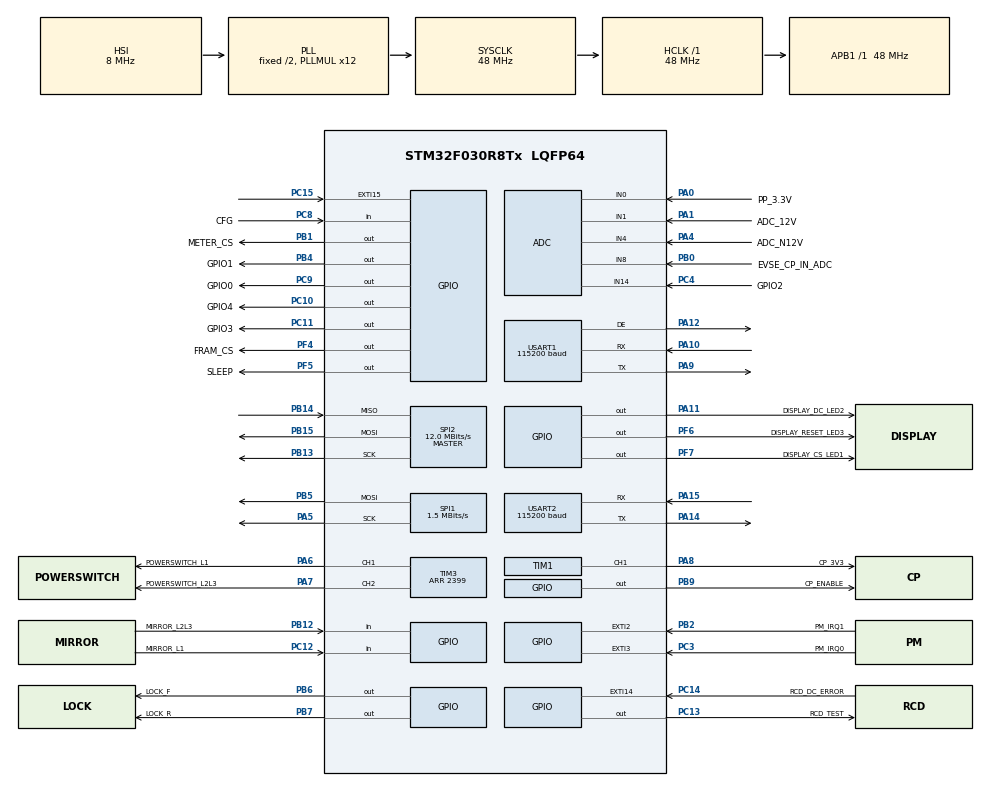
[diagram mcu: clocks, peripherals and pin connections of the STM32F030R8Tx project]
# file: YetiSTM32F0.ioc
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ADC.EOCSelection=ADC_EOC_SEQ_CONV
ADC.Overrun=ADC_OVR_DATA_OVERWRITTEN
ADC.SamplingTime=ADC_SAMPLETIME_13CYCLES_5
CRC.InputDataInversionMode=CRC_INPUTDATA_INVERSION_BYTE
CRC.OutputDataInversionMode=CRC_OUTPUTDATA_INVERSION_ENABLE
Dma.ADC.0.Direction=DMA_PERIPH_TO_MEMORY
Dma.ADC.0.Instance=DMA1_Channel1
Dma.ADC.0.MemDataAlignment=DMA_MDATAALIGN_HALFWORD
Dma.ADC.0.MemInc=DMA_MINC_ENABLE
Dma.ADC.0.Mode=DMA_NORMAL
Dma.ADC.0.PeriphDataAlignment=DMA_PDATAALIGN_HALFWORD
Dma.ADC.0.PeriphInc=DMA_PINC_DISABLE
Dma.ADC.0.Priority=DMA_PRIORITY_HIGH
Dma.Request0=ADC
Dma.Request1=USART2_TX
Dma.Request2=USART2_RX
Dma.Request3=SPI1_TX
Dma.SPI1_TX.3.Direction=DMA_MEMORY_TO_PERIPH
Dma.SPI1_TX.3.Instance=DMA1_Channel3
Dma.SPI1_TX.3.MemDataAlignment=DMA_MDATAALIGN_BYTE
Dma.SPI1_TX.3.MemInc=DMA_MINC_ENABLE
Dma.SPI1_TX.3.Mode=DMA_NORMAL
Dma.SPI1_TX.3.PeriphDataAlignment=DMA_PDATAALIGN_BYTE
Dma.SPI1_TX.3.PeriphInc=DMA_PINC_DISABLE
Dma.SPI1_TX.3.Priority=DMA_PRIORITY_LOW
Dma.USART2_RX.2.Direction=DMA_PERIPH_TO_MEMORY
Dma.USART2_RX.2.Instance=DMA1_Channel5
Dma.USART2_RX.2.MemDataAlignment=DMA_MDATAALIGN_BYTE
Dma.USART2_RX.2.MemInc=DMA_MINC_ENABLE
Dma.USART2_RX.2.Mode=DMA_CIRCULAR
Dma.USART2_RX.2.PeriphDataAlignment=DMA_PDATAALIGN_BYTE
Dma.USART2_RX.2.PeriphInc=DMA_PINC_DISABLE
Dma.USART2_RX.2.Priority=DMA_PRIORITY_LOW
Dma.USART2_TX.1.Direction=DMA_MEMORY_TO_PERIPH
Dma.USART2_TX.1.Instance=DMA1_Channel4
Dma.USART2_TX.1.MemDataAlignment=DMA_MDATAALIGN_BYTE
Dma.USART2_TX.1.MemInc=DMA_MINC_ENABLE
Dma.USART2_TX.1.Mode=DMA_NORMAL
Dma.USART2_TX.1.PeriphDataAlignment=DMA_PDATAALIGN_BYTE
Dma.USART2_TX.1.PeriphInc=DMA_PINC_DISABLE
Dma.USART2_TX.1.Priority=DMA_PRIORITY_LOW
Mcu.Family=STM32F0
Mcu.Name=STM32F030R8Tx
Mcu.Package=LQFP64
NVIC.DMA1_Channel1_IRQn=true\:0\:0\:false\:false\:true\:false\:true\:true
NVIC.DMA1_Channel2_3_IRQn=true\:0\:0\:false\:false\:true\:false\:true\:true
NVIC.DMA1_Channel4_5_IRQn=true\:0\:0\:false\:false\:true\:false\:true\:true
NVIC.EXTI2_3_IRQn=true\:0\:0\:false\:false\:true\:true\:true\:true
NVIC.EXTI4_15_IRQn=true\:0\:0\:false\:false\:true\:true\:true\:true
NVIC.TIM1_BRK_UP_TRG_COM_IRQn=true\:0\:0\:false\:false\:true\:true\:true\:true
NVIC.TIM1_CC_IRQn=true\:0\:0\:false\:false\:true\:true\:true\:true
NVIC.USART2_IRQn=true\:0\:0\:false\:false\:true\:true\:true\:true
PA0.GPIO_Label=PP_3.3V
PA0.Mode=IN0
PA0.Signal=ADC_IN0
PA1.GPIO_Label=ADC_12V
PA1.Mode=IN1
PA1.Signal=ADC_IN1
PA10.GPIO_Speed=GPIO_SPEED_FREQ_LOW
PA10.Mode=Asynchronous
PA10.Signal=USART1_RX
PA11.GPIO_Label=DISPLAY_DC_LED2
PA11.Signal=GPIO_Output
PA12.GPIO_Speed=GPIO_SPEED_FREQ_LOW
PA12.Mode=Hardware Flow Control (RS485)
PA12.Signal=USART1_DE
PA14.GPIO_PuPd=GPIO_PULLUP
PA14.GPIO_Speed=GPIO_SPEED_FREQ_LOW
PA14.Mode=Asynchronous
PA14.Signal=USART2_TX
PA15.GPIO_PuPd=GPIO_PULLUP
PA15.GPIO_Speed=GPIO_SPEED_FREQ_LOW
PA15.Mode=Asynchronous
PA15.Signal=USART2_RX
PA4.GPIO_Label=ADC_N12V
PA4.Mode=IN4
PA4.Signal=ADC_IN4
PA5.Mode=TX_Only_Simplex_Unidirect_Master
PA5.Signal=SPI1_SCK
PA6.GPIO_Label=POWERSWITCH_L1
PA6.GPIO_PuPd=GPIO_PULLDOWN
PA6.Signal=S_TIM3_CH1
PA7.GPIO_Label=POWERSWITCH_L2L3
PA7.GPIO_PuPd=GPIO_PULLDOWN
PA7.Signal=S_TIM3_CH2
PA8.GPIO_Label=CP_3V3
PA8.Signal=S_TIM1_CH1
PA9.GPIO_Speed=GPIO_SPEED_FREQ_LOW
PA9.Mode=Asynchronous
PA9.Signal=USART1_TX
PB0.GPIO_Label=EVSE_CP_IN_ADC
PB0.Mode=IN8
PB0.Signal=ADC_IN8
PB1.GPIO_Label=METER_CS
PB1.GPIO_PuPd=GPIO_PULLUP
PB1.Signal=GPIO_Output
PB12.GPIO_Label=MIRROR_L2L3
PB12.GPIO_PuPd=GPIO_PULLDOWN
PB12.Signal=GPIO_Input
PB13.Mode=Full_Duplex_Master
PB13.Signal=SPI2_SCK
PB14.Mode=Full_Duplex_Master
PB14.Signal=SPI2_MISO
PB15.Mode=Full_Duplex_Master
PB15.Signal=SPI2_MOSI
PB2.GPIO_Label=PM_IRQ1
PB2.GPIO_PuPd=GPIO_PULLUP
PB2.Signal=GPXTI2
PB4.GPIO_Label=GPIO1
PB4.Signal=GPIO_Output
PB5.Mode=TX_Only_Simplex_Unidirect_Master
PB5.Signal=SPI1_MOSI
PB6.GPIO_Label=LOCK_F
PB6.Signal=GPIO_Output
PB7.GPIO_Label=LOCK_R
PB7.Signal=GPIO_Output
PB9.GPIO_Label=CP_ENABLE
PB9.Signal=GPIO_Output
PC10.GPIO_Label=GPIO4
PC10.Signal=GPIO_Output
PC11.GPIO_Label=GPIO3
PC11.Signal=GPIO_Output
PC12.GPIO_Label=MIRROR_L1
PC12.GPIO_PuPd=GPIO_PULLDOWN
PC12.Signal=GPIO_Input
PC13.GPIO_Label=RCD_TEST
PC13.Signal=GPIO_Output
PC14-OSC32_IN.GPIO_Label=RCD_DC_ERROR
PC14-OSC32_IN.GPIO_PuPd=GPIO_PULLDOWN
PC14-OSC32_IN.Signal=GPXTI14
PC15-OSC32_OUT.Signal=GPXTI15
PC3.GPIO_Label=PM_IRQ0
PC3.GPIO_PuPd=GPIO_PULLUP
PC3.Signal=GPXTI3
PC4.GPIO_Label=GPIO2
PC4.Mode=IN14
PC4.Signal=ADC_IN14
PC8.GPIO_Label=CFG
PC8.GPIO_PuPd=GPIO_PULLUP
PC8.Signal=GPIO_Input
PC9.GPIO_Label=GPIO0
PC9.Signal=GPIO_Output
PF4.GPIO_Label=FRAM_CS
PF4.GPIO_PuPd=GPIO_PULLUP
PF4.Signal=GPIO_Output
PF5.GPIO_Label=SLEEP
PF5.GPIO_PuPd=GPIO_PULLUP
PF5.PinState=GPIO_PIN_SET
PF5.Signal=GPIO_Output
PF6.GPIO_Label=DISPLAY_RESET_LED3
PF6.Signal=GPIO_Output
PF7.GPIO_Label=DISPLAY_CS_LED1
PF7.Signal=GPIO_Output
ProjectManager.HeapSize=0x200
ProjectManager.StackSize=0x400
ProjectManager.TargetToolchain=STM32CubeIDE
RCC.AHBFreq_Value=48000000
RCC.APB1Freq_Value=48000000
RCC.APB1TimFreq_Value=48000000
RCC.HCLKFreq_Value=48000000
RCC.HSE_VALUE=32000000
RCC.PLLMUL=RCC_PLL_MUL12
RCC.SYSCLKFreq_VALUE=48000000
RCC.SYSCLKSource=RCC_SYSCLKSOURCE_PLLCLK
SH.S_TIM1_CH1.0=TIM1_CH1,Output Compare1 CH1
SH.S_TIM3_CH1.0=TIM3_CH1,PWM Generation1 CH1
SH.S_TIM3_CH2.0=TIM3_CH2,PWM Generation2 CH2
SPI1.BaudRatePrescaler=SPI_BAUDRATEPRESCALER_32
SPI1.CLKPhase=SPI_PHASE_2EDGE
SPI1.CLKPolarity=SPI_POLARITY_HIGH
SPI1.CalculateBaudRate=1.5 MBits/s
SPI1.DataSize=SPI_DATASIZE_8BIT
SPI1.Direction=SPI_DIRECTION_2LINES
SPI1.Mode=SPI_MODE_MASTER
SPI1.VirtualType=VM_MASTER
SPI2.BaudRatePrescaler=SPI_BAUDRATEPRESCALER_4
SPI2.CLKPhase=SPI_PHASE_2EDGE
SPI2.CLKPolarity=SPI_POLARITY_HIGH
SPI2.CalculateBaudRate=12.0 MBits/s
SPI2.DataSize=SPI_DATASIZE_8BIT
SPI2.Direction=SPI_DIRECTION_2LINES
SPI2.Mode=SPI_MODE_MASTER
SPI2.VirtualType=VM_MASTER
TIM1.Channel-Output\ Compare1\ CH1=TIM_CHANNEL_1
TIM1.Channel-Output\ Compare2\ No\ Output=TIM_CHANNEL_2
TIM1.Channel-Output\ Compare3\ No\ Output=TIM_CHANNEL_3
TIM1.Channel-PWM\ Generation1\ CH1=TIM_CHANNEL_1
TIM1.OC1Preload=ENABLE
TIM1.OC2Preload=ENABLE
TIM1.OC3Preload=ENABLE
TIM1.OCMode_1=TIM_OCMODE_TOGGLE
TIM1.OCMode_2=TIM_OCMODE_TOGGLE
TIM1.OCMode_3=TIM_OCMODE_TOGGLE
TIM1.Period=47999
TIM1.Prescaler=0
TIM1.Pulse-Output\ Compare1\ CH1=32767
TIM1.Pulse-Output\ Compare2\ No\ Output=200
TIM1.Pulse-Output\ Compare3\ No\ Output=45500
TIM1.Pulse-PWM\ Generation1\ CH1=32767
TIM3.Channel-PWM\ Generation1\ CH1=TIM_CHANNEL_1
TIM3.Channel-PWM\ Generation2\ CH2=TIM_CHANNEL_2
TIM3.Period=2399
USART1.BaudRate=115200
USART1.VirtualMode-Asynchronous=VM_ASYNC
USART1.VirtualMode-Hardware\ Flow\ Control\ (RS485)=VM_ASYNC
USART2.BaudRate=115200
USART2.VirtualMode-Asynchronous=VM_ASYNC
VP_ADC_TempSens_Input.Mode=IN-TempSens
VP_ADC_Vref_Input.Mode=IN-Vrefint
VP_CRC_VS_CRC.Mode=CRC_Activate
VP_TIM1_VS_no_output2.Mode=Output Compare2 No Output
VP_TIM1_VS_no_output3.Mode=Output Compare3 No Output
board=custom

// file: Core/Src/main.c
/* USER CODE BEGIN Header */
/**
  ******************************************************************************
  * @file           : main.c
  * @brief          : Main program body
  ******************************************************************************
  * @attention
  *
  * Copyright (c) 2024 STMicroelectronics.
  * All rights reserved.
  *
  * This software is licensed under terms that can be found in the LICENSE file
  * in the root directory of this software component.
  * If no LICENSE file comes with this software, it is provided AS-IS.
  *
  ******************************************************************************
  */
/* USER CODE END Header */
#include "main.h"
#include "startpoint.h"

ADC_HandleTypeDef hadc;
DMA_HandleTypeDef hdma_adc;

CRC_HandleTypeDef hcrc;

SPI_HandleTypeDef hspi1;
SPI_HandleTypeDef hspi2;
DMA_HandleTypeDef hdma_spi1_tx;

TIM_HandleTypeDef htim1;
TIM_HandleTypeDef htim3;

UART_HandleTypeDef huart1;
UART_HandleTypeDef huart2;
DMA_HandleTypeDef hdma_usart2_tx;
DMA_HandleTypeDef hdma_usart2_rx;

void SystemClock_Config(void);
static void MX_GPIO_Init(void);
static void MX_DMA_Init(void);
static void MX_TIM1_Init(void);
static void MX_ADC_Init(void);
static void MX_TIM3_Init(void);
static void MX_SPI1_Init(void);
static void MX_SPI2_Init(void);
static void MX_USART2_UART_Init(void);
static void MX_CRC_Init(void);
static void MX_USART1_UART_Init(void);

int main(void)
{

  /* MCU Configuration--------------------------------------------------------*/

  /* Reset of all peripherals, Initializes the Flash interface and the Systick. */
  HAL_Init();

  /* Configure the system clock */
  SystemClock_Config();

  /* Initialize all configured peripherals */
  MX_GPIO_Init();
  MX_DMA_Init();
  MX_TIM1_Init();
  MX_ADC_Init();
  MX_TIM3_Init();
  MX_SPI1_Init();
  MX_SPI2_Init();
  MX_USART2_UART_Init();
  MX_CRC_Init();
  MX_USART1_UART_Init();

  /* Infinite loop */
  while (1)
  {

    /* USER CODE BEGIN 3 */
	  //samy

	  start();

  }
  /* USER CODE END 3 */
}

void SystemClock_Config(void)
{
  RCC_OscInitTypeDef RCC_OscInitStruct = {0};
  RCC_ClkInitTypeDef RCC_ClkInitStruct = {0};
  RCC_PeriphCLKInitTypeDef PeriphClkInit = {0};

  /** Initializes the RCC Oscillators according to the specified parameters
  * in the RCC_OscInitTypeDef structure.
  */
  RCC_OscInitStruct.OscillatorType = RCC_OSCILLATORTYPE_HSI|RCC_OSCILLATORTYPE_HSI14;
  RCC_OscInitStruct.HSIState = RCC_HSI_ON;
  RCC_OscInitStruct.HSI14State = RCC_HSI14_ON;
  RCC_OscInitStruct.HSICalibrationValue = RCC_HSICALIBRATION_DEFAULT;
  RCC_OscInitStruct.HSI14CalibrationValue = 16;
  RCC_OscInitStruct.PLL.PLLState = RCC_PLL_ON;
  RCC_OscInitStruct.PLL.PLLSource = RCC_PLLSOURCE_HSI;
  RCC_OscInitStruct.PLL.PLLMUL = RCC_PLL_MUL12;
  RCC_OscInitStruct.PLL.PREDIV = RCC_PREDIV_DIV1;
  if (HAL_RCC_OscConfig(&RCC_OscInitStruct) != HAL_OK)
  {
    Error_Handler();
  }

  /** Initializes the CPU, AHB and APB buses clocks
  */
  RCC_ClkInitStruct.ClockType = RCC_CLOCKTYPE_HCLK|RCC_CLOCKTYPE_SYSCLK
                              |RCC_CLOCKTYPE_PCLK1;
  RCC_ClkInitStruct.SYSCLKSource = RCC_SYSCLKSOURCE_PLLCLK;
  RCC_ClkInitStruct.AHBCLKDivider = RCC_SYSCLK_DIV1;
  RCC_ClkInitStruct.APB1CLKDivider = RCC_HCLK_DIV1;

  if (HAL_RCC_ClockConfig(&RCC_ClkInitStruct, FLASH_LATENCY_1) != HAL_OK)
  {
    Error_Handler();
  }
  PeriphClkInit.PeriphClockSelection = RCC_PERIPHCLK_USART1;
  PeriphClkInit.Usart1ClockSelection = RCC_USART1CLKSOURCE_PCLK1;
  if (HAL_RCCEx_PeriphCLKConfig(&PeriphClkInit) != HAL_OK)
  {
    Error_Handler();
  }
}

static void MX_ADC_Init(void)
{

  ADC_ChannelConfTypeDef sConfig = {0};

  /** Configure the global features of the ADC (Clock, Resolution, Data Alignment and number of conversion)
  */
  hadc.Instance = ADC1;
  hadc.Init.ClockPrescaler = ADC_CLOCK_ASYNC_DIV1;
  hadc.Init.Resolution = ADC_RESOLUTION_12B;
  hadc.Init.DataAlign = ADC_DATAALIGN_RIGHT;
  hadc.Init.ScanConvMode = ADC_SCAN_DIRECTION_FORWARD;
  hadc.Init.EOCSelection = ADC_EOC_SEQ_CONV;
  hadc.Init.LowPowerAutoWait = DISABLE;
  hadc.Init.LowPowerAutoPowerOff = DISABLE;
  hadc.Init.ContinuousConvMode = DISABLE;
  hadc.Init.DiscontinuousConvMode = DISABLE;
  hadc.Init.ExternalTrigConv = ADC_SOFTWARE_START;
  hadc.Init.ExternalTrigConvEdge = ADC_EXTERNALTRIGCONVEDGE_NONE;
  hadc.Init.DMAContinuousRequests = DISABLE;
  hadc.Init.Overrun = ADC_OVR_DATA_OVERWRITTEN;
  if (HAL_ADC_Init(&hadc) != HAL_OK)
  {
    Error_Handler();
  }

  /** Configure for the selected ADC regular channel to be converted.
  */
  sConfig.Channel = ADC_CHANNEL_0;
  sConfig.Rank = ADC_RANK_CHANNEL_NUMBER;
  sConfig.SamplingTime = ADC_SAMPLETIME_13CYCLES_5;
  if (HAL_ADC_ConfigChannel(&hadc, &sConfig) != HAL_OK)
  {
    Error_Handler();
  }

  /** Configure for the selected ADC regular channel to be converted.
  */
  sConfig.Channel = ADC_CHANNEL_1;
  if (HAL_ADC_ConfigChannel(&hadc, &sConfig) != HAL_OK)
  {
    Error_Handler();
  }

  /** Configure for the selected ADC regular channel to be converted.
  */
  sConfig.Channel = ADC_CHANNEL_4;
  if (HAL_ADC_ConfigChannel(&hadc, &sConfig) != HAL_OK)
  {
    Error_Handler();
  }

  /** Configure for the selected ADC regular channel to be converted.
  */
  sConfig.Channel = ADC_CHANNEL_8;
  if (HAL_ADC_ConfigChannel(&hadc, &sConfig) != HAL_OK)
  {
    Error_Handler();
  }

  /** Configure for the selected ADC regular channel to be converted.
  */
  sConfig.Channel = ADC_CHANNEL_14;
  if (HAL_ADC_ConfigChannel(&hadc, &sConfig) != HAL_OK)
  {
    Error_Handler();
  }

  /** Configure for the selected ADC regular channel to be converted.
  */
  sConfig.Channel = ADC_CHANNEL_TEMPSENSOR;
  if (HAL_ADC_ConfigChannel(&hadc, &sConfig) != HAL_OK)
  {
    Error_Handler();
  }

  /** Configure for the selected ADC regular channel to be converted.
  */
  sConfig.Channel = ADC_CHANNEL_VREFINT;
  if (HAL_ADC_ConfigChannel(&hadc, &sConfig) != HAL_OK)
  {
    Error_Handler();
  }

}

static void MX_CRC_Init(void)
{

  hcrc.Instance = CRC;
  hcrc.Init.DefaultInitValueUse = DEFAULT_INIT_VALUE_ENABLE;
  hcrc.Init.InputDataInversionMode = CRC_INPUTDATA_INVERSION_BYTE;
  hcrc.Init.OutputDataInversionMode = CRC_OUTPUTDATA_INVERSION_ENABLE;
  hcrc.InputDataFormat = CRC_INPUTDATA_FORMAT_BYTES;
  if (HAL_CRC_Init(&hcrc) != HAL_OK)
  {
    Error_Handler();
  }

}

static void MX_SPI1_Init(void)
{

  /* SPI1 parameter configuration*/
  hspi1.Instance = SPI1;
  hspi1.Init.Mode = SPI_MODE_MASTER;
  hspi1.Init.Direction = SPI_DIRECTION_2LINES;
  hspi1.Init.DataSize = SPI_DATASIZE_8BIT;
  hspi1.Init.CLKPolarity = SPI_POLARITY_HIGH;
  hspi1.Init.CLKPhase = SPI_PHASE_2EDGE;
  hspi1.Init.NSS = SPI_NSS_SOFT;
  hspi1.Init.BaudRatePrescaler = SPI_BAUDRATEPRESCALER_32;
  hspi1.Init.FirstBit = SPI_FIRSTBIT_MSB;
  hspi1.Init.TIMode = SPI_TIMODE_DISABLE;
  hspi1.Init.CRCCalculation = SPI_CRCCALCULATION_DISABLE;
  hspi1.Init.CRCPolynomial = 7;
  hspi1.Init.CRCLength = SPI_CRC_LENGTH_DATASIZE;
  hspi1.Init.NSSPMode = SPI_NSS_PULSE_DISABLE;
  if (HAL_SPI_Init(&hspi1) != HAL_OK)
  {
    Error_Handler();
  }

}

static void MX_SPI2_Init(void)
{

  /* SPI2 parameter configuration*/
  hspi2.Instance = SPI2;
  hspi2.Init.Mode = SPI_MODE_MASTER;
  hspi2.Init.Direction = SPI_DIRECTION_2LINES;
  hspi2.Init.DataSize = SPI_DATASIZE_8BIT;
  hspi2.Init.CLKPolarity = SPI_POLARITY_HIGH;
  hspi2.Init.CLKPhase = SPI_PHASE_2EDGE;
  hspi2.Init.NSS = SPI_NSS_SOFT;
  hspi2.Init.BaudRatePrescaler = SPI_BAUDRATEPRESCALER_4;
  hspi2.Init.FirstBit = SPI_FIRSTBIT_MSB;
  hspi2.Init.TIMode = SPI_TIMODE_DISABLE;
  hspi2.Init.CRCCalculation = SPI_CRCCALCULATION_DISABLE;
  hspi2.Init.CRCPolynomial = 7;
  hspi2.Init.CRCLength = SPI_CRC_LENGTH_DATASIZE;
  hspi2.Init.NSSPMode = SPI_NSS_PULSE_DISABLE;
  if (HAL_SPI_Init(&hspi2) != HAL_OK)
  {
    Error_Handler();
  }

}

static void MX_TIM1_Init(void)
{

  TIM_MasterConfigTypeDef sMasterConfig = {0};
  TIM_OC_InitTypeDef sConfigOC = {0};
  TIM_BreakDeadTimeConfigTypeDef sBreakDeadTimeConfig = {0};

  htim1.Instance = TIM1;
  htim1.Init.Prescaler = 0;
  htim1.Init.CounterMode = TIM_COUNTERMODE_UP;
  htim1.Init.Period = 47999;
  htim1.Init.ClockDivision = TIM_CLOCKDIVISION_DIV1;
  htim1.Init.RepetitionCounter = 0;
  htim1.Init.AutoReloadPreload = TIM_AUTORELOAD_PRELOAD_DISABLE;
  if (HAL_TIM_OC_Init(&htim1) != HAL_OK)
  {
    Error_Handler();
  }
  sMasterConfig.MasterOutputTrigger = TIM_TRGO_RESET;
  sMasterConfig.MasterSlaveMode = TIM_MASTERSLAVEMODE_DISABLE;
  if (HAL_TIMEx_MasterConfigSynchronization(&htim1, &sMasterConfig) != HAL_OK)
  {
    Error_Handler();
  }
  sConfigOC.OCMode = TIM_OCMODE_TOGGLE;
  sConfigOC.Pulse = 32767;
  sConfigOC.OCPolarity = TIM_OCPOLARITY_HIGH;
  sConfigOC.OCNPolarity = TIM_OCNPOLARITY_HIGH;
  sConfigOC.OCFastMode = TIM_OCFAST_DISABLE;
  sConfigOC.OCIdleState = TIM_OCIDLESTATE_RESET;
  sConfigOC.OCNIdleState = TIM_OCNIDLESTATE_RESET;
  if (HAL_TIM_OC_ConfigChannel(&htim1, &sConfigOC, TIM_CHANNEL_1) != HAL_OK)
  {
    Error_Handler();
  }
  __HAL_TIM_ENABLE_OCxPRELOAD(&htim1, TIM_CHANNEL_1);
  sConfigOC.Pulse = 200;
  if (HAL_TIM_OC_ConfigChannel(&htim1, &sConfigOC, TIM_CHANNEL_2) != HAL_OK)
  {
    Error_Handler();
  }
  __HAL_TIM_ENABLE_OCxPRELOAD(&htim1, TIM_CHANNEL_2);
  sConfigOC.Pulse = 45500;
  if (HAL_TIM_OC_ConfigChannel(&htim1, &sConfigOC, TIM_CHANNEL_3) != HAL_OK)
  {
    Error_Handler();
  }
  __HAL_TIM_ENABLE_OCxPRELOAD(&htim1, TIM_CHANNEL_3);
  sBreakDeadTimeConfig.OffStateRunMode = TIM_OSSR_DISABLE;
  sBreakDeadTimeConfig.OffStateIDLEMode = TIM_OSSI_DISABLE;
  sBreakDeadTimeConfig.LockLevel = TIM_LOCKLEVEL_OFF;
  sBreakDeadTimeConfig.DeadTime = 0;
  sBreakDeadTimeConfig.BreakState = TIM_BREAK_DISABLE;
  sBreakDeadTimeConfig.BreakPolarity = TIM_BREAKPOLARITY_HIGH;
  sBreakDeadTimeConfig.AutomaticOutput = TIM_AUTOMATICOUTPUT_DISABLE;
  if (HAL_TIMEx_ConfigBreakDeadTime(&htim1, &sBreakDeadTimeConfig) != HAL_OK)
  {
    Error_Handler();
  }
  HAL_TIM_MspPostInit(&htim1);

}

static void MX_TIM3_Init(void)
{

  TIM_MasterConfigTypeDef sMasterConfig = {0};
  TIM_OC_InitTypeDef sConfigOC = {0};

  htim3.Instance = TIM3;
  htim3.Init.Prescaler = 0;
  htim3.Init.CounterMode = TIM_COUNTERMODE_UP;
  htim3.Init.Period = 2399;
  htim3.Init.ClockDivision = TIM_CLOCKDIVISION_DIV1;
  htim3.Init.AutoReloadPreload = TIM_AUTORELOAD_PRELOAD_DISABLE;
  if (HAL_TIM_PWM_Init(&htim3) != HAL_OK)
  {
    Error_Handler();
  }
  sMasterConfig.MasterOutputTrigger = TIM_TRGO_RESET;
  sMasterConfig.MasterSlaveMode = TIM_MASTERSLAVEMODE_DISABLE;
  if (HAL_TIMEx_MasterConfigSynchronization(&htim3, &sMasterConfig) != HAL_OK)
  {
    Error_Handler();
  }
  sConfigOC.OCMode = TIM_OCMODE_PWM1;
  sConfigOC.Pulse = 0;
  sConfigOC.OCPolarity = TIM_OCPOLARITY_HIGH;
  sConfigOC.OCFastMode = TIM_OCFAST_DISABLE;
  if (HAL_TIM_PWM_ConfigChannel(&htim3, &sConfigOC, TIM_CHANNEL_1) != HAL_OK)
  {
    Error_Handler();
  }
  if (HAL_TIM_PWM_ConfigChannel(&htim3, &sConfigOC, TIM_CHANNEL_2) != HAL_OK)
  {
    Error_Handler();
  }
  HAL_TIM_MspPostInit(&htim3);

}

static void MX_USART1_UART_Init(void)
{

  huart1.Instance = USART1;
  huart1.Init.BaudRate = 115200;
  huart1.Init.WordLength = UART_WORDLENGTH_8B;
  huart1.Init.StopBits = UART_STOPBITS_1;
  huart1.Init.Parity = UART_PARITY_NONE;
  huart1.Init.Mode = UART_MODE_TX_RX;
  huart1.Init.HwFlowCtl = UART_HWCONTROL_NONE;
  huart1.Init.OverSampling = UART_OVERSAMPLING_16;
  huart1.Init.OneBitSampling = UART_ONE_BIT_SAMPLE_DISABLE;
  huart1.AdvancedInit.AdvFeatureInit = UART_ADVFEATURE_NO_INIT;
  if (HAL_RS485Ex_Init(&huart1, UART_DE_POLARITY_HIGH, 0, 0) != HAL_OK)
  {
    Error_Handler();
  }

}

static void MX_USART2_UART_Init(void)
{

  huart2.Instance = USART2;
  huart2.Init.BaudRate = 9600; //115200;
  huart2.Init.WordLength = UART_WORDLENGTH_8B;
  huart2.Init.StopBits = UART_STOPBITS_1;
  huart2.Init.Parity = UART_PARITY_NONE;
  huart2.Init.Mode = UART_MODE_TX_RX;
  huart2.Init.HwFlowCtl = UART_HWCONTROL_NONE;
  huart2.Init.OverSampling = UART_OVERSAMPLING_16;
  huart2.Init.OneBitSampling = UART_ONE_BIT_SAMPLE_DISABLE;
  huart2.AdvancedInit.AdvFeatureInit = UART_ADVFEATURE_NO_INIT;
  if (HAL_UART_Init(&huart2) != HAL_OK)
  {
    Error_Handler();
  }

}

static void MX_DMA_Init(void)
{

  /* DMA controller clock enable */
  __HAL_RCC_DMA1_CLK_ENABLE();

  /* DMA interrupt init */
  /* DMA1_Channel1_IRQn interrupt configuration */
  HAL_NVIC_SetPriority(DMA1_Channel1_IRQn, 0, 0);
  HAL_NVIC_EnableIRQ(DMA1_Channel1_IRQn);
  /* DMA1_Channel2_3_IRQn interrupt configuration */
  HAL_NVIC_SetPriority(DMA1_Channel2_3_IRQn, 0, 0);
  HAL_NVIC_EnableIRQ(DMA1_Channel2_3_IRQn);
  /* DMA1_Channel4_5_IRQn interrupt configuration */
  HAL_NVIC_SetPriority(DMA1_Channel4_5_IRQn, 0, 0);
  HAL_NVIC_EnableIRQ(DMA1_Channel4_5_IRQn);

}

static void MX_GPIO_Init(void)
{
  GPIO_InitTypeDef GPIO_InitStruct = {0};

  /* GPIO Ports Clock Enable */
  __HAL_RCC_GPIOC_CLK_ENABLE();
  __HAL_RCC_GPIOA_CLK_ENABLE();
  __HAL_RCC_GPIOF_CLK_ENABLE();
  __HAL_RCC_GPIOB_CLK_ENABLE();

  /*Configure GPIO pin Output Level */
  HAL_GPIO_WritePin(GPIOC, RCD_TEST_Pin|GPIO0_Pin|GPIO4_Pin|GPIO3_Pin, GPIO_PIN_RESET);

  /*Configure GPIO pin Output Level */
  HAL_GPIO_WritePin(GPIOF, FRAM_CS_Pin|DISPLAY_RESET_LED3_Pin|DISPLAY_CS_LED1_Pin, GPIO_PIN_RESET);

  /*Configure GPIO pin Output Level */
  HAL_GPIO_WritePin(SLEEP_GPIO_Port, SLEEP_Pin, GPIO_PIN_SET);

  /*Configure GPIO pin Output Level */
  HAL_GPIO_WritePin(GPIOB, METER_CS_Pin|GPIO1_Pin|LOCK_F_Pin|LOCK_R_Pin
                          |CP_ENABLE_Pin, GPIO_PIN_RESET);

  /*Configure GPIO pin Output Level */
  HAL_GPIO_WritePin(DISPLAY_DC_LED2_GPIO_Port, DISPLAY_DC_LED2_Pin, GPIO_PIN_RESET);

  /*Configure GPIO pins : RCD_TEST_Pin GPIO0_Pin GPIO4_Pin GPIO3_Pin */
  GPIO_InitStruct.Pin = RCD_TEST_Pin|GPIO0_Pin|GPIO4_Pin|GPIO3_Pin;
  GPIO_InitStruct.Mode = GPIO_MODE_OUTPUT_PP;
  GPIO_InitStruct.Pull = GPIO_NOPULL;
  GPIO_InitStruct.Speed = GPIO_SPEED_FREQ_LOW;
  HAL_GPIO_Init(GPIOC, &GPIO_InitStruct);

  /*Configure GPIO pin : RCD_DC_ERROR_Pin */
  GPIO_InitStruct.Pin = RCD_DC_ERROR_Pin;
  GPIO_InitStruct.Mode = GPIO_MODE_IT_RISING;
  GPIO_InitStruct.Pull = GPIO_PULLDOWN;
  HAL_GPIO_Init(RCD_DC_ERROR_GPIO_Port, &GPIO_InitStruct);

  /*Configure GPIO pin : PC15 */
  GPIO_InitStruct.Pin = GPIO_PIN_15;
  GPIO_InitStruct.Mode = GPIO_MODE_IT_RISING;
  GPIO_InitStruct.Pull = GPIO_NOPULL;
  HAL_GPIO_Init(GPIOC, &GPIO_InitStruct);

  /*Configure GPIO pin : PM_IRQ0_Pin */
  GPIO_InitStruct.Pin = PM_IRQ0_Pin;
  GPIO_InitStruct.Mode = GPIO_MODE_IT_RISING;
  GPIO_InitStruct.Pull = GPIO_PULLUP;
  HAL_GPIO_Init(PM_IRQ0_GPIO_Port, &GPIO_InitStruct);

  /*Configure GPIO pins : FRAM_CS_Pin SLEEP_Pin */
  GPIO_InitStruct.Pin = FRAM_CS_Pin|SLEEP_Pin;
  GPIO_InitStruct.Mode = GPIO_MODE_OUTPUT_PP;
  GPIO_InitStruct.Pull = GPIO_PULLUP;
  GPIO_InitStruct.Speed = GPIO_SPEED_FREQ_LOW;
  HAL_GPIO_Init(GPIOF, &GPIO_InitStruct);

  /*Configure GPIO pin : METER_CS_Pin */
  GPIO_InitStruct.Pin = METER_CS_Pin;
  GPIO_InitStruct.Mode = GPIO_MODE_OUTPUT_PP;
  GPIO_InitStruct.Pull = GPIO_PULLUP;
  GPIO_InitStruct.Speed = GPIO_SPEED_FREQ_LOW;
  HAL_GPIO_Init(METER_CS_GPIO_Port, &GPIO_InitStruct);

  /*Configure GPIO pin : PM_IRQ1_Pin */
  GPIO_InitStruct.Pin = PM_IRQ1_Pin;
  GPIO_InitStruct.Mode = GPIO_MODE_IT_RISING;
  GPIO_InitStruct.Pull = GPIO_PULLUP;
  HAL_GPIO_Init(PM_IRQ1_GPIO_Port, &GPIO_InitStruct);

  /*Configure GPIO pin : MIRROR_L2L3_Pin */
  GPIO_InitStruct.Pin = MIRROR_L2L3_Pin;
  GPIO_InitStruct.Mode = GPIO_MODE_INPUT;
  GPIO_InitStruct.Pull = GPIO_PULLDOWN;
  HAL_GPIO_Init(MIRROR_L2L3_GPIO_Port, &GPIO_InitStruct);

  /*Configure GPIO pin : CFG_Pin */
  GPIO_InitStruct.Pin = CFG_Pin;
  GPIO_InitStruct.Mode = GPIO_MODE_INPUT;
  GPIO_InitStruct.Pull = GPIO_PULLUP;
  HAL_GPIO_Init(CFG_GPIO_Port, &GPIO_InitStruct);

  /*Configure GPIO pin : DISPLAY_DC_LED2_Pin */
  GPIO_InitStruct.Pin = DISPLAY_DC_LED2_Pin;
  GPIO_InitStruct.Mode = GPIO_MODE_OUTPUT_PP;
  GPIO_InitStruct.Pull = GPIO_NOPULL;
  GPIO_InitStruct.Speed = GPIO_SPEED_FREQ_LOW;
  HAL_GPIO_Init(DISPLAY_DC_LED2_GPIO_Port, &GPIO_InitStruct);

  /*Configure GPIO pins : DISPLAY_RESET_LED3_Pin DISPLAY_CS_LED1_Pin */
  GPIO_InitStruct.Pin = DISPLAY_RESET_LED3_Pin|DISPLAY_CS_LED1_Pin;
  GPIO_InitStruct.Mode = GPIO_MODE_OUTPUT_PP;
  GPIO_InitStruct.Pull = GPIO_NOPULL;
  GPIO_InitStruct.Speed = GPIO_SPEED_FREQ_LOW;
  HAL_GPIO_Init(GPIOF, &GPIO_InitStruct);

  /*Configure GPIO pin : MIRROR_L1_Pin */
  GPIO_InitStruct.Pin = MIRROR_L1_Pin;
  GPIO_InitStruct.Mode = GPIO_MODE_INPUT;
  GPIO_InitStruct.Pull = GPIO_PULLDOWN;
  HAL_GPIO_Init(MIRROR_L1_GPIO_Port, &GPIO_InitStruct);

  /*Configure GPIO pins : GPIO1_Pin LOCK_F_Pin LOCK_R_Pin CP_ENABLE_Pin */
  GPIO_InitStruct.Pin = GPIO1_Pin|LOCK_F_Pin|LOCK_R_Pin|CP_ENABLE_Pin;
  GPIO_InitStruct.Mode = GPIO_MODE_OUTPUT_PP;
  GPIO_InitStruct.Pull = GPIO_NOPULL;
  GPIO_InitStruct.Speed = GPIO_SPEED_FREQ_LOW;
  HAL_GPIO_Init(GPIOB, &GPIO_InitStruct);

  /* EXTI interrupt init*/
  HAL_NVIC_SetPriority(EXTI2_3_IRQn, 0, 0);
  HAL_NVIC_EnableIRQ(EXTI2_3_IRQn);

  HAL_NVIC_SetPriority(EXTI4_15_IRQn, 0, 0);
  HAL_NVIC_EnableIRQ(EXTI4_15_IRQn);

}

void Error_Handler(void)
{
  __disable_irq();
  while (1)
  {
  }
}
